VERSION "created by canmatrix"

NS_ :

BS_:

BU_: BMS Third_Party_Device INV VCU U2C

BO_ 3221225472 VECTOR__INDEPENDENT_SIG_MSG: 0 Vector__XXX
 SG_ New_Signal_159 : 0|8@1+ (1,0) [0|0] "" Vector__XXX

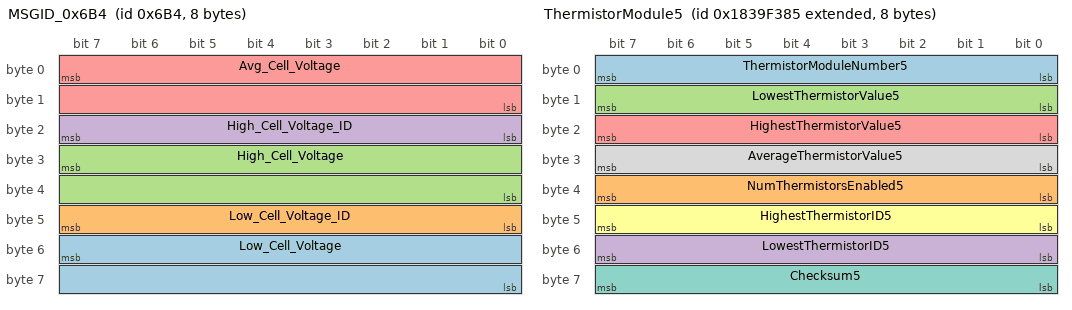
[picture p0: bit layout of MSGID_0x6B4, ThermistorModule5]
BO_ 1716 MSGID_0x6B4: 8 Vector__XXX
 SG_ Low_Cell_Voltage : 55|16@0+ (0.0001,0) [0|0] "V" Vector__XXX
 SG_ Low_Cell_Voltage_ID : 47|8@0+ (1,1720) [0|0] "ID" Vector__XXX
 SG_ High_Cell_Voltage : 31|16@0+ (0.0001,0) [0|0] "V" Vector__XXX
 SG_ High_Cell_Voltage_ID : 23|8@0+ (1,0) [0|0] "ID" Vector__XXX
 SG_ Avg_Cell_Voltage : 7|16@0+ (0.0001,0) [0|0] "V" Vector__XXX

BO_ 2553934725 ThermistorModule5: 8 Vector__XXX
 SG_ ThermistorModuleNumber5 : 0|8@1- (1,0) [0|0] "" Vector__XXX
 SG_ NumThermistorsEnabled5 : 32|8@1- (1,0) [0|0] "" Vector__XXX
 SG_ LowestThermistorValue5 : 8|8@1- (1,0) [0|0] "Celsius" Vector__XXX
 SG_ LowestThermistorID5 : 48|8@1- (1,0) [0|0] "" Vector__XXX
 SG_ HighestThermistorValue5 : 16|8@1- (1,0) [0|0] "Celsius" Vector__XXX
 SG_ HighestThermistorID5 : 40|8@1- (1,0) [0|0] "" Vector__XXX
 SG_ Checksum5 : 56|8@1+ (1,0) [0|0] "" Vector__XXX
 SG_ AverageThermistorValue5 : 24|8@1- (1,0) [0|0] "Celsius" Vector__XXX

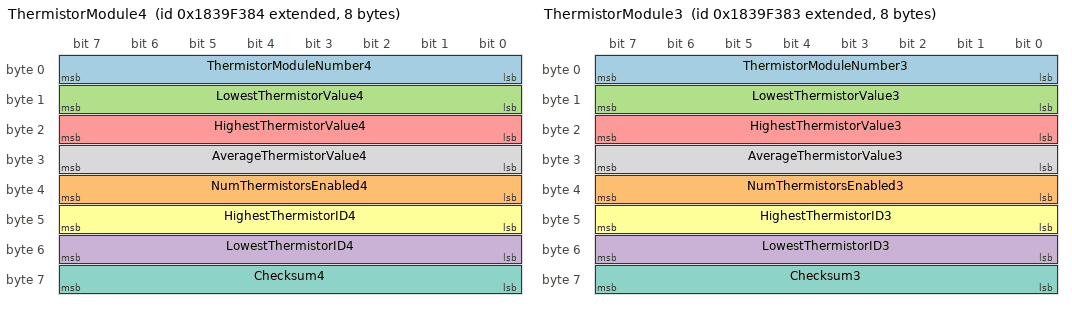
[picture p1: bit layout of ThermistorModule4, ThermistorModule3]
BO_ 2553934724 ThermistorModule4: 8 Vector__XXX
 SG_ ThermistorModuleNumber4 : 0|8@1- (1,0) [0|0] "" Vector__XXX
 SG_ NumThermistorsEnabled4 : 32|8@1- (1,0) [0|0] "" Vector__XXX
 SG_ LowestThermistorValue4 : 8|8@1- (1,0) [0|0] "Celsius" Vector__XXX
 SG_ LowestThermistorID4 : 48|8@1- (1,0) [0|0] "" Vector__XXX
 SG_ HighestThermistorValue4 : 16|8@1- (1,0) [0|0] "Celsius" Vector__XXX
 SG_ HighestThermistorID4 : 40|8@1- (1,0) [0|0] "" Vector__XXX
 SG_ Checksum4 : 56|8@1+ (1,0) [0|0] "" Vector__XXX
 SG_ AverageThermistorValue4 : 24|8@1- (1,0) [0|0] "Celsius" Vector__XXX

BO_ 2553934723 ThermistorModule3: 8 Vector__XXX
 SG_ ThermistorModuleNumber3 : 0|8@1- (1,0) [0|0] "" Vector__XXX
 SG_ NumThermistorsEnabled3 : 32|8@1- (1,0) [0|0] "" Vector__XXX
 SG_ LowestThermistorValue3 : 8|8@1- (1,0) [0|0] "Celsius" Vector__XXX
 SG_ LowestThermistorID3 : 48|8@1- (1,0) [0|0] "" Vector__XXX
 SG_ HighestThermistorValue3 : 16|8@1- (1,0) [0|0] "Celsius" Vector__XXX
 SG_ HighestThermistorID3 : 40|8@1- (1,0) [0|0] "" Vector__XXX
 SG_ Checksum3 : 56|8@1+ (1,0) [0|0] "" Vector__XXX
 SG_ AverageThermistorValue3 : 24|8@1- (1,0) [0|0] "Celsius" Vector__XXX

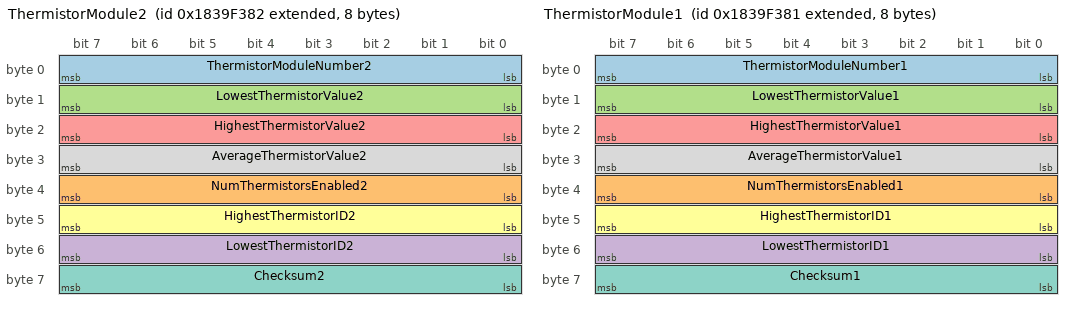
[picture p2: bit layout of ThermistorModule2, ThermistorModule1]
BO_ 2553934722 ThermistorModule2: 8 Vector__XXX
 SG_ ThermistorModuleNumber2 : 0|8@1- (1,0) [0|0] "" Vector__XXX
 SG_ NumThermistorsEnabled2 : 32|8@1- (1,0) [0|0] "" Vector__XXX
 SG_ LowestThermistorValue2 : 8|8@1- (1,0) [0|0] "Celsius" Vector__XXX
 SG_ LowestThermistorID2 : 48|8@1- (1,0) [0|0] "" Vector__XXX
 SG_ HighestThermistorValue2 : 16|8@1- (1,0) [0|0] "Celsius" Vector__XXX
 SG_ HighestThermistorID2 : 40|8@1- (1,0) [0|0] "" Vector__XXX
 SG_ Checksum2 : 56|8@1+ (1,0) [0|0] "" Vector__XXX
 SG_ AverageThermistorValue2 : 24|8@1- (1,0) [0|0] "Celsius" Vector__XXX

BO_ 2553934721 ThermistorModule1: 8 Vector__XXX
 SG_ ThermistorModuleNumber1 : 0|8@1- (1,0) [0|0] "" Vector__XXX
 SG_ NumThermistorsEnabled1 : 32|8@1- (1,0) [0|0] "" Vector__XXX
 SG_ LowestThermistorValue1 : 8|8@1- (1,0) [0|0] "Celsius" Vector__XXX
 SG_ LowestThermistorID1 : 48|8@1- (1,0) [0|0] "" Vector__XXX
 SG_ HighestThermistorValue1 : 16|8@1- (1,0) [0|0] "Celsius" Vector__XXX
 SG_ HighestThermistorID1 : 40|8@1- (1,0) [0|0] "" Vector__XXX
 SG_ Checksum1 : 56|8@1+ (1,0) [0|0] "" Vector__XXX
 SG_ AverageThermistorValue1 : 24|8@1- (1,0) [0|0] "Celsius" Vector__XXX

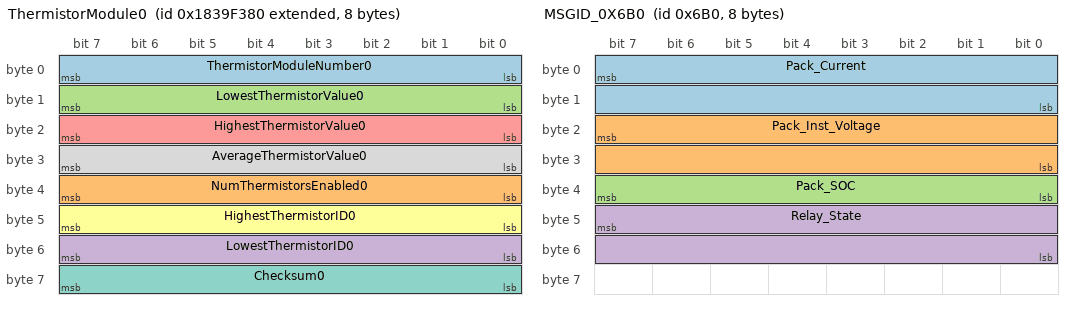
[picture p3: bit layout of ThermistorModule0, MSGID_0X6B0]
BO_ 2553934720 ThermistorModule0: 8 Vector__XXX
 SG_ ThermistorModuleNumber0 : 0|8@1- (1,0) [0|0] "" Vector__XXX
 SG_ NumThermistorsEnabled0 : 32|8@1- (1,0) [0|0] "" Vector__XXX
 SG_ LowestThermistorValue0 : 8|8@1- (1,0) [0|0] "Celsius" Vector__XXX
 SG_ LowestThermistorID0 : 48|8@1- (1,0) [0|0] "" Vector__XXX
 SG_ HighestThermistorValue0 : 16|8@1- (1,0) [0|0] "Celsius" Vector__XXX
 SG_ HighestThermistorID0 : 40|8@1- (1,0) [0|0] "" Vector__XXX
 SG_ Checksum0 : 56|8@1+ (1,0) [0|0] "" Vector__XXX
 SG_ AverageThermistorValue0 : 24|8@1- (1,0) [0|0] "Celsius" Vector__XXX

BO_ 1712 MSGID_0X6B0: 8 BMS
 SG_ Pack_Current : 7|16@0+ (0.1,0) [0|0] "A"  Third_Party_Device
 SG_ Pack_Inst_Voltage : 23|16@0+ (0.1,0) [0|0] "V"  Third_Party_Device
 SG_ Pack_SOC : 39|8@0+ (0.5,0) [0|0] "Percent"  Third_Party_Device
 SG_ Relay_State : 47|16@0+ (1,0) [0|0] ""  Third_Party_Device

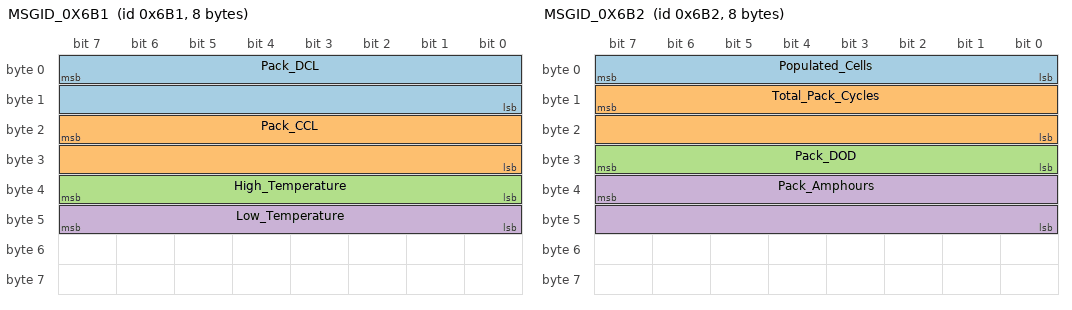
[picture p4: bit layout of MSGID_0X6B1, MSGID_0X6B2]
BO_ 1713 MSGID_0X6B1: 8 BMS
 SG_ Pack_DCL : 7|16@0+ (1,0) [0|0] "A"  Third_Party_Device
 SG_ Pack_CCL : 23|16@0+ (1,0) [0|0] "Amp"  Third_Party_Device
 SG_ High_Temperature : 39|8@0+ (1,0) [0|0] "Celsius"  Third_Party_Device
 SG_ Low_Temperature : 47|8@0+ (1,0) [0|0] "Celsius"  Third_Party_Device

BO_ 1714 MSGID_0X6B2: 8 BMS
 SG_ Populated_Cells : 7|8@0+ (1,0) [0|0] ""  Third_Party_Device
 SG_ Total_Pack_Cycles : 15|16@0+ (1,0) [0|0] ""  Third_Party_Device
 SG_ Pack_DOD : 31|8@0+ (0.5,0) [0|0] "Percent"  Third_Party_Device
 SG_ Pack_Amphours : 39|16@0+ (0.1,0) [0|0] "Amphours"  Third_Party_Device

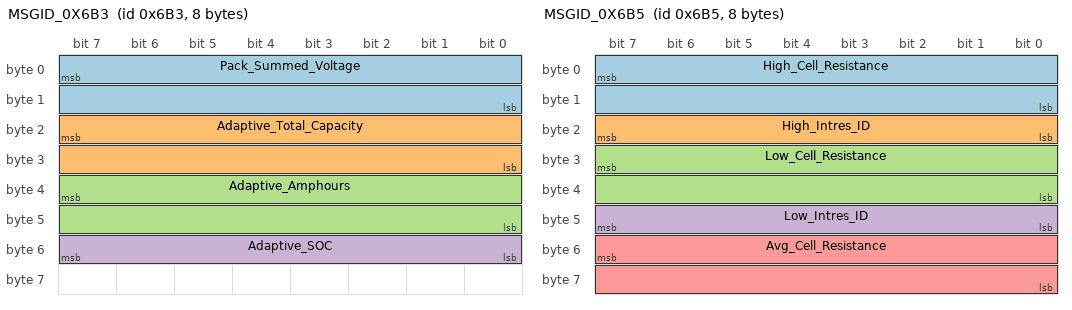
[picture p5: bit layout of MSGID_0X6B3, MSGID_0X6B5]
BO_ 1715 MSGID_0X6B3: 8 BMS
 SG_ Pack_Summed_Voltage : 7|16@0+ (0.01,0) [0|0] "V"  Third_Party_Device
 SG_ Adaptive_Total_Capacity : 23|16@0+ (0.1,0) [0|0] "Amphours"  Third_Party_Device
 SG_ Adaptive_Amphours : 39|16@0+ (0.1,0) [0|0] "Amphours"  Third_Party_Device
 SG_ Adaptive_SOC : 55|8@0+ (0.5,0) [0|0] "Percent"  Third_Party_Device

BO_ 1717 MSGID_0X6B5: 8 BMS
 SG_ High_Cell_Resistance : 7|16@0+ (0.01,0) [0|0] "mOhm"  Third_Party_Device
 SG_ High_Intres_ID : 23|8@0+ (1,0) [0|0] "ID"  Third_Party_Device
 SG_ Low_Cell_Resistance : 31|16@0+ (0.01,0) [0|0] "mOhm"  Third_Party_Device
 SG_ Low_Intres_ID : 47|8@0+ (1,0) [0|0] "ID"  Third_Party_Device
 SG_ Avg_Cell_Resistance : 55|16@0+ (0.01,0) [0|0] "mOhm"  Third_Party_Device

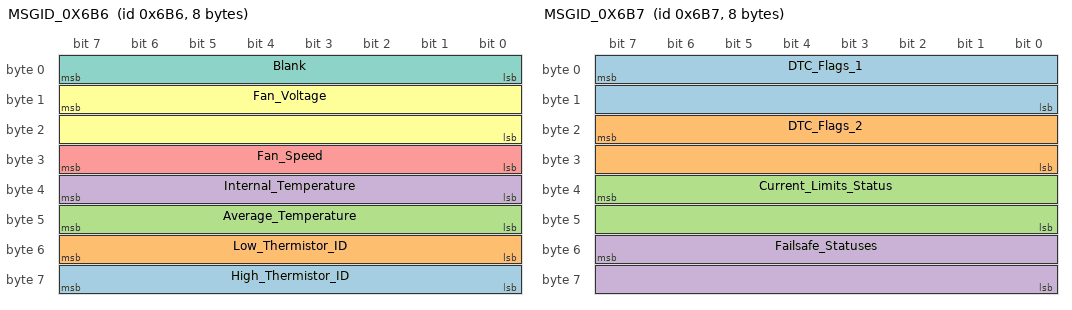
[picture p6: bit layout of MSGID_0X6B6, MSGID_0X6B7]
BO_ 1718 MSGID_0X6B6: 8 BMS
 SG_ High_Thermistor_ID : 63|8@0+ (1,0) [0|0] "ID"  Third_Party_Device
 SG_ Low_Thermistor_ID : 55|8@0+ (1,0) [0|0] "ID"  Third_Party_Device
 SG_ Average_Temperature : 47|8@0+ (1,0) [0|0] "Celsius"  Third_Party_Device
 SG_ Internal_Temperature : 39|8@0+ (1,0) [0|0] "Celsius"  Third_Party_Device
 SG_ Fan_Speed : 31|8@0+ (1,0) [0|0] "Speed"  Third_Party_Device
 SG_ Fan_Voltage : 15|16@0+ (0.01,0) [0|0] "Volts"  Third_Party_Device
 SG_ Blank : 7|8@0+ (1,0) [0|0] ""  Third_Party_Device

BO_ 1719 MSGID_0X6B7: 8 BMS
 SG_ DTC_Flags_1 : 7|16@0+ (1,0) [0|0] ""  Third_Party_Device
 SG_ DTC_Flags_2 : 23|16@0+ (1,0) [0|0] ""  Third_Party_Device
 SG_ Current_Limits_Status : 39|16@0+ (1,0) [0|0] ""  Third_Party_Device
 SG_ Failsafe_Statuses : 55|16@0+ (1,0) [0|0] ""  Third_Party_Device

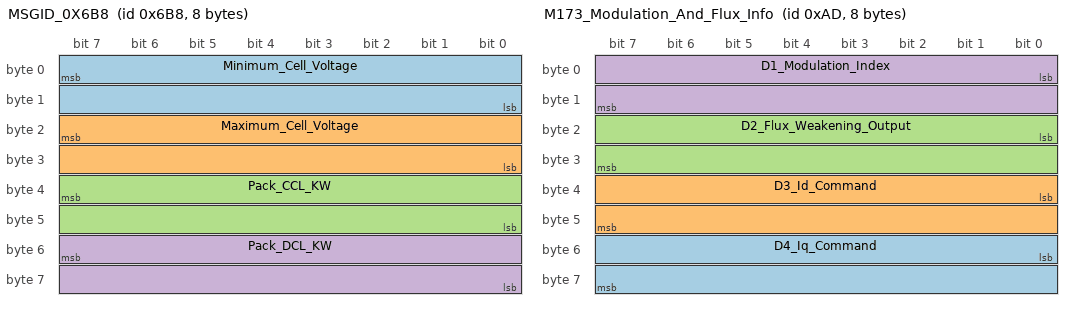
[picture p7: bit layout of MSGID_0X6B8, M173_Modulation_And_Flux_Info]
BO_ 1720 MSGID_0X6B8: 8 BMS
 SG_ Minimum_Cell_Voltage : 7|16@0+ (0.0001,0) [0|0] "Volts"  Third_Party_Device
 SG_ Maximum_Cell_Voltage : 23|16@0+ (0.0001,0) [0|0] "Volts"  Third_Party_Device
 SG_ Pack_CCL_KW : 39|16@0+ (0.1,0) [0|0] "kW"  Third_Party_Device
 SG_ Pack_DCL_KW : 55|16@0+ (0.1,0) [0|0] "kW"  Third_Party_Device

BO_ 173 M173_Modulation_And_Flux_Info: 8 INV
 SG_ D4_Iq_Command : 48|16@1- (0.1,0) [-3276.8|3276.7] "A" Vector__XXX
 SG_ D3_Id_Command : 32|16@1- (0.1,0) [-3276.8|3276.7] "A" Vector__XXX
 SG_ D2_Flux_Weakening_Output : 16|16@1- (0.1,0) [-3276.8|3276.7] "A" Vector__XXX
 SG_ D1_Modulation_Index : 0|16@1- (0.01,0) [-327.68|327.67] "" Vector__XXX

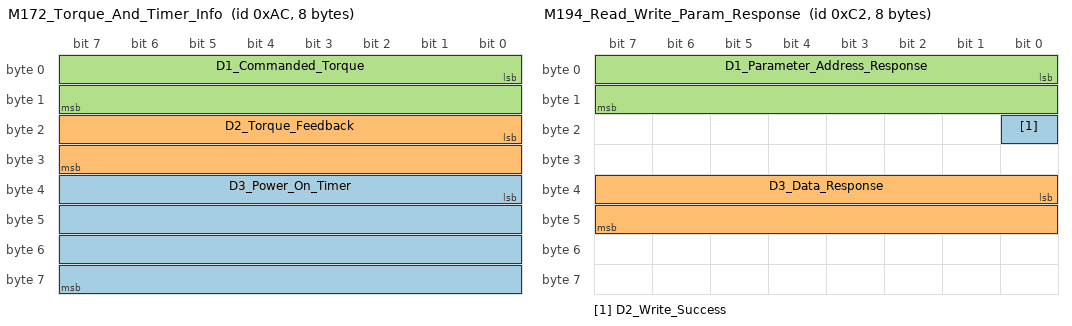
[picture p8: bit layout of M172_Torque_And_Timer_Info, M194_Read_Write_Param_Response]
BO_ 172 M172_Torque_And_Timer_Info: 8 INV
 SG_ D3_Power_On_Timer : 32|32@1+ (1,0) [0|4294967295] "Sec" Vector__XXX
 SG_ D2_Torque_Feedback : 16|16@1- (0.1,0) [-3276.8|3276.7] "Nm" Vector__XXX
 SG_ D1_Commanded_Torque : 0|16@1- (0.1,0) [-3276.8|3276.7] "Nm" Vector__XXX

BO_ 194 M194_Read_Write_Param_Response: 8 INV
 SG_ D2_Write_Success : 16|1@1+ (1,0) [0|1] "" Vector__XXX
 SG_ D3_Data_Response : 32|16@1- (1,0) [-32768|32767] "" Vector__XXX
 SG_ D1_Parameter_Address_Response : 0|16@1+ (1,0) [0|65535] "" Vector__XXX

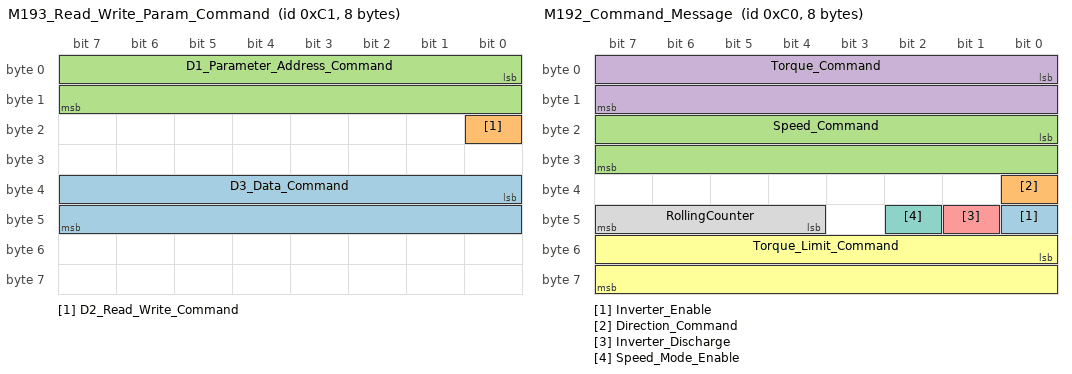
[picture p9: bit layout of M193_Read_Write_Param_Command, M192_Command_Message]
BO_ 193 M193_Read_Write_Param_Command: 8 VCU
 SG_ D3_Data_Command : 32|16@1- (1,0) [-32768|32767] "" Vector__XXX
 SG_ D2_Read_Write_Command : 16|1@1+ (1,0) [0|1] "" Vector__XXX
 SG_ D1_Parameter_Address_Command : 0|16@1+ (1,0) [0|65535] "" Vector__XXX

BO_ 192 M192_Command_Message: 8 VCU
 SG_ Inverter_Enable : 40|1@1+ (1,0) [0|1] "Bit" Vector__XXX
 SG_ Direction_Command : 32|1@1+ (1,0) [0|1] "Bit" Vector__XXX
 SG_ Speed_Command : 16|16@1- (1,0) [-32768|32767] "rpm" Vector__XXX
 SG_ Torque_Command : 0|16@1- (0.1,0) [-3276.8|3276.7] "Nm" Vector__XXX
 SG_ Inverter_Discharge : 41|1@1+ (1,0) [0|1] "Bit" Vector__XXX
 SG_ Torque_Limit_Command : 48|16@1- (0.1,0) [-3276.8|3276.7] "Nm" Vector__XXX
 SG_ Speed_Mode_Enable : 42|1@1+ (1,0) [0|1] "Bit" Vector__XXX
 SG_ RollingCounter : 44|4@1+ (1,0) [0|15] "Bits" Vector__XXX

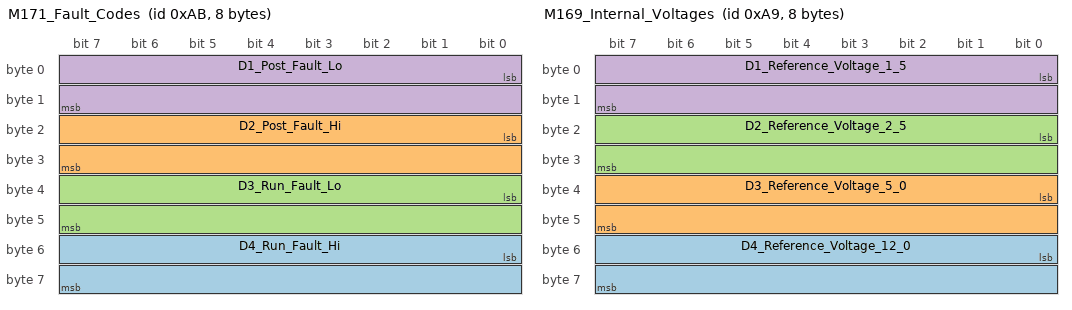
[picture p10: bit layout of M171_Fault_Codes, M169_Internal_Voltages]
BO_ 171 M171_Fault_Codes: 8 INV
 SG_ D4_Run_Fault_Hi : 48|16@1+ (1,0) [0|65535] "" Vector__XXX
 SG_ D2_Post_Fault_Hi : 16|16@1+ (1,0) [0|65535] "" Vector__XXX
 SG_ D3_Run_Fault_Lo : 32|16@1+ (1,0) [0|65535] "" Vector__XXX
 SG_ D1_Post_Fault_Lo : 0|16@1+ (1,0) [0|65535] "" Vector__XXX

BO_ 170 M170_Internal_States: 8 INV
 SG_ D7_Direction_Command : 56|1@1+ (1,0) [0|1] "" Vector__XXX
 SG_ D6_Inverter_Enable_State : 48|1@1+ (1,0) [0|1] "" Vector__XXX
 SG_ D3_Relay_3_Status : 26|1@1+ (1,0) [0|1] "" Vector__XXX
 SG_ D3_Relay_4_Status : 27|1@1+ (1,0) [0|1] "" Vector__XXX
 SG_ D3_Relay_2_Status : 25|1@1+ (1,0) [0|1] "" Vector__XXX
 SG_ D4_Inverter_Run_Mode : 32|1@1+ (1,0) [0|1] "" Vector__XXX
 SG_ D5_Inverter_Command_Mode : 40|1@1+ (1,0) [0|1] "" Vector__XXX
 SG_ D3_Relay_1_Status : 24|1@1+ (1,0) [0|1] "" Vector__XXX
 SG_ D2_Inverter_State : 16|8@1+ (1,0) [0|255] "" Vector__XXX
 SG_ D1_VSM_State : 0|8@1+ (1,0) [0|15] "" Vector__XXX
 SG_ D6_Inverter_Enable_Lockout : 55|1@1+ (1,0) [0|1] "" Vector__XXX
 SG_ D4_Inverter_Discharge_State : 37|3@1+ (1,0) [0|7] "" Vector__XXX
 SG_ D3_Relay_5_Status : 28|1@1+ (1,0) [0|1] "" Vector__XXX
 SG_ D3_Relay_6_Status : 29|1@1+ (1,0) [0|1] "" Vector__XXX
 SG_ D7_BMS_Active : 57|1@1+ (1,0) [0|1] "" Vector__XXX
 SG_ D7_BMS_Torque_Limiting : 58|1@1+ (1,0) [0|1] "" Vector__XXX
 SG_ D7_Max_Speed_Limiting : 59|1@1+ (1,0) [0|1] "" Vector__XXX
 SG_ D7_Low_Speed_Limiting : 61|1@1+ (1,0) [0|1] "" Vector__XXX
 SG_ D5_Rolling_Counter : 44|4@1+ (1,0) [0|15] "" Vector__XXX
 SG_ D1_PWM_Frequency : 8|8@1+ (1,0) [0|255] "kHz" Vector__XXX
 SG_ D6_Start_Mode_Active : 54|1@1+ (1,0) [0|1] "" Vector__XXX

BO_ 169 M169_Internal_Voltages: 8 INV
 SG_ D4_Reference_Voltage_12_0 : 48|16@1- (0.01,0) [-327.68|327.67] "V" Vector__XXX
 SG_ D3_Reference_Voltage_5_0 : 32|16@1- (0.01,0) [-327.68|327.67] "V" Vector__XXX
 SG_ D2_Reference_Voltage_2_5 : 16|16@1- (0.01,0) [-327.68|327.67] "V" Vector__XXX
 SG_ D1_Reference_Voltage_1_5 : 0|16@1- (0.01,0) [-327.68|327.67] "V" Vector__XXX

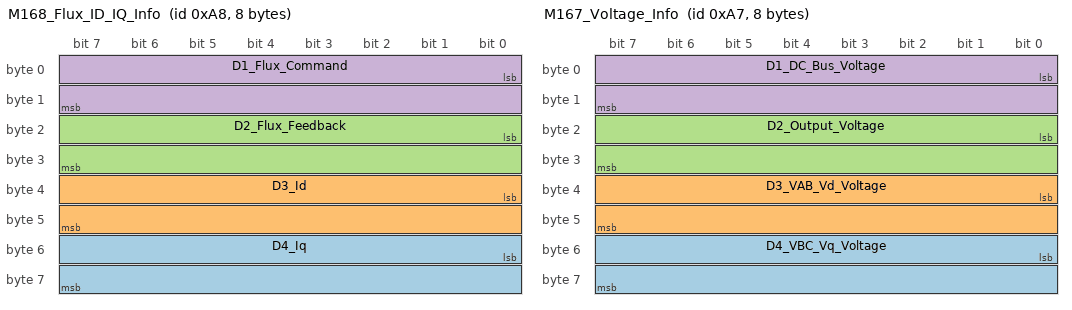
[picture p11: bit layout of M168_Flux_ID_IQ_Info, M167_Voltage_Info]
BO_ 168 M168_Flux_ID_IQ_Info: 8 INV
 SG_ D4_Iq : 48|16@1- (0.1,0) [-3276.8|3276.7] "A" Vector__XXX
 SG_ D3_Id : 32|16@1- (0.1,0) [-3276.8|3276.7] "A" Vector__XXX
 SG_ D2_Flux_Feedback : 16|16@1- (0.001,0) [-32.768|32.767] "Wb" Vector__XXX
 SG_ D1_Flux_Command : 0|16@1- (0.001,0) [-32.768|32.767] "Wb" Vector__XXX

BO_ 167 M167_Voltage_Info: 8 INV
 SG_ D4_VBC_Vq_Voltage : 48|16@1- (0.1,0) [-3276.8|3276.7] "V" Vector__XXX
 SG_ D3_VAB_Vd_Voltage : 32|16@1- (0.1,0) [-3276.8|3276.7] "V" Vector__XXX
 SG_ D2_Output_Voltage : 16|16@1- (0.1,0) [-3276.8|3276.7] "V" Vector__XXX
 SG_ D1_DC_Bus_Voltage : 0|16@1- (0.1,0) [-3276.8|3276.7] "V" Vector__XXX

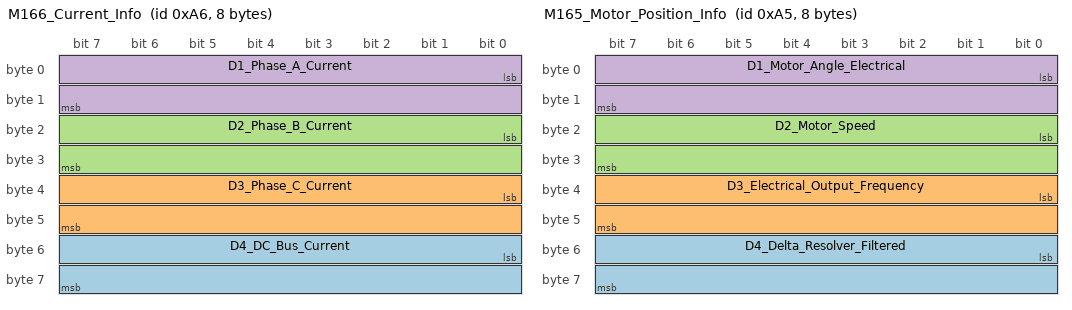
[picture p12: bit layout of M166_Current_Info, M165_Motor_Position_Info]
BO_ 166 M166_Current_Info: 8 INV
 SG_ D4_DC_Bus_Current : 48|16@1- (0.1,0) [-3276.8|3276.7] "A" Vector__XXX
 SG_ D3_Phase_C_Current : 32|16@1- (0.1,0) [-3276.8|3276.7] "A" Vector__XXX
 SG_ D2_Phase_B_Current : 16|16@1- (0.1,0) [-3276.8|3276.7] "A" Vector__XXX
 SG_ D1_Phase_A_Current : 0|16@1- (0.1,0) [-3276.8|3276.7] "A" Vector__XXX

BO_ 165 M165_Motor_Position_Info: 8 INV
 SG_ D4_Delta_Resolver_Filtered : 48|16@1- (0.1,0) [-3276.8|3276.7] "deg" Vector__XXX
 SG_ D3_Electrical_Output_Frequency : 32|16@1- (0.1,0) [-3276.8|3276.7] "hz" Vector__XXX
 SG_ D2_Motor_Speed : 16|16@1- (1,0) [-32768|32767] "rpm" Vector__XXX
 SG_ D1_Motor_Angle_Electrical : 0|16@1- (0.1,0) [-3276.8|3276.7] "deg" Vector__XXX

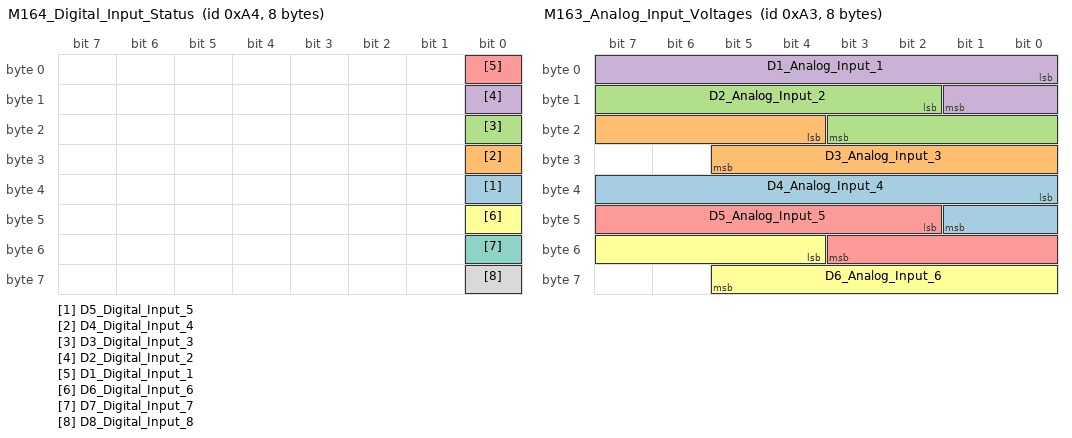
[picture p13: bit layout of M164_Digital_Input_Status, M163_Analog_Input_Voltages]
BO_ 164 M164_Digital_Input_Status: 8 INV
 SG_ D5_Digital_Input_5 : 32|1@1+ (1,0) [0|1] "boolean" Vector__XXX
 SG_ D4_Digital_Input_4 : 24|1@1+ (1,0) [0|1] "boolean" Vector__XXX
 SG_ D3_Digital_Input_3 : 16|1@1+ (1,0) [0|1] "boolean" Vector__XXX
 SG_ D2_Digital_Input_2 : 8|1@1+ (1,0) [0|1] "boolean" Vector__XXX
 SG_ D1_Digital_Input_1 : 0|1@1+ (1,0) [0|1] "boolean" Vector__XXX
 SG_ D6_Digital_Input_6 : 40|1@1+ (1,0) [0|1] "boolean" Vector__XXX
 SG_ D7_Digital_Input_7 : 48|1@1+ (1,0) [0|1] "boolean" Vector__XXX
 SG_ D8_Digital_Input_8 : 56|1@1+ (1,0) [0|1] "boolean" Vector__XXX

BO_ 163 M163_Analog_Input_Voltages: 8 INV
 SG_ D4_Analog_Input_4 : 32|10@1- (0.01,0) [-5.12|5.11] "V" Vector__XXX
 SG_ D3_Analog_Input_3 : 20|10@1- (0.01,0) [-5.12|5.11] "V" Vector__XXX
 SG_ D2_Analog_Input_2 : 10|10@1- (0.01,0) [-5.12|5.11] "V" Vector__XXX
 SG_ D1_Analog_Input_1 : 0|10@1- (0.01,0) [-5.12|5.11] "V" Vector__XXX
 SG_ D5_Analog_Input_5 : 42|10@1- (0.01,0) [-5.12|5.11] "V" Vector__XXX
 SG_ D6_Analog_Input_6 : 52|10@1- (0.01,0) [-5.12|5.11] "V" Vector__XXX

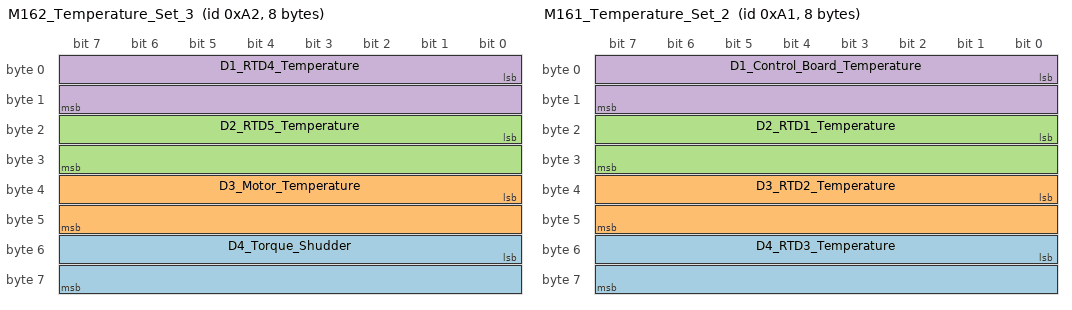
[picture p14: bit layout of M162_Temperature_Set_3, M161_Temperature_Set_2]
BO_ 162 M162_Temperature_Set_3: 8 INV
 SG_ D4_Torque_Shudder : 48|16@1- (0.1,0) [-3276.8|3276.7] "Nm" Vector__XXX
 SG_ D3_Motor_Temperature : 32|16@1- (0.1,0) [-3276.8|3276.7] "degC" Vector__XXX
 SG_ D2_RTD5_Temperature : 16|16@1- (0.1,0) [-3276.8|3276.7] "degC" Vector__XXX
 SG_ D1_RTD4_Temperature : 0|16@1- (0.1,0) [-3276.8|3276.7] "degC" Vector__XXX

BO_ 161 M161_Temperature_Set_2: 8 INV
 SG_ D4_RTD3_Temperature : 48|16@1- (0.1,0) [-3276.8|3276.7] "degC" Vector__XXX
 SG_ D3_RTD2_Temperature : 32|16@1- (0.1,0) [-3276.8|3276.7] "degC" Vector__XXX
 SG_ D2_RTD1_Temperature : 16|16@1- (0.1,0) [-3276.8|3276.7] "degC" Vector__XXX
 SG_ D1_Control_Board_Temperature : 0|16@1- (0.1,0) [-3276.8|3276.7] "degC" Vector__XXX

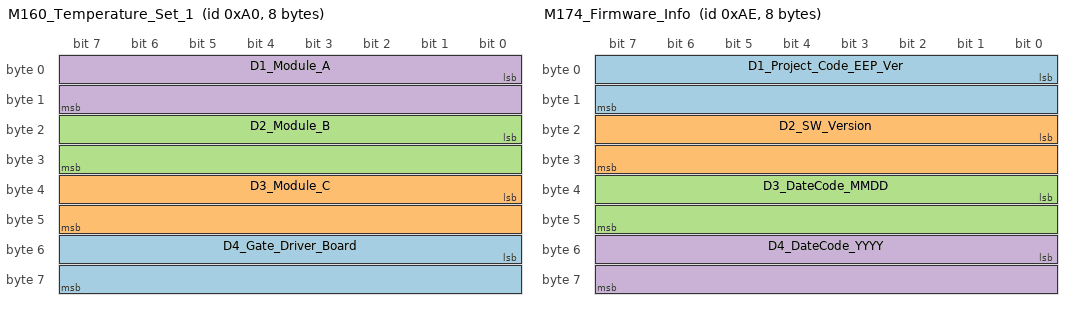
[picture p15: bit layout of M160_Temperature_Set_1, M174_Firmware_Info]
BO_ 160 M160_Temperature_Set_1: 8 INV
 SG_ D4_Gate_Driver_Board : 48|16@1- (0.1,0) [-3276.8|3276.7] "degC" Vector__XXX
 SG_ D3_Module_C : 32|16@1- (0.1,0) [-3276.8|3276.7] "degC" Vector__XXX
 SG_ D2_Module_B : 16|16@1- (0.1,0) [-3276.8|3276.7] "degC" Vector__XXX
 SG_ D1_Module_A : 0|16@1- (0.1,0) [-3276.8|3276.7] "degC" Vector__XXX

BO_ 174 M174_Firmware_Info: 8 INV
 SG_ D1_Project_Code_EEP_Ver : 0|16@1+ (1,0) [0|65535] "" Vector__XXX
 SG_ D2_SW_Version : 16|16@1+ (1,0) [0|65535] "" Vector__XXX
 SG_ D3_DateCode_MMDD : 32|16@1+ (1,0) [0|65535] "" Vector__XXX
 SG_ D4_DateCode_YYYY : 48|16@1+ (1,0) [0|65535] "" Vector__XXX

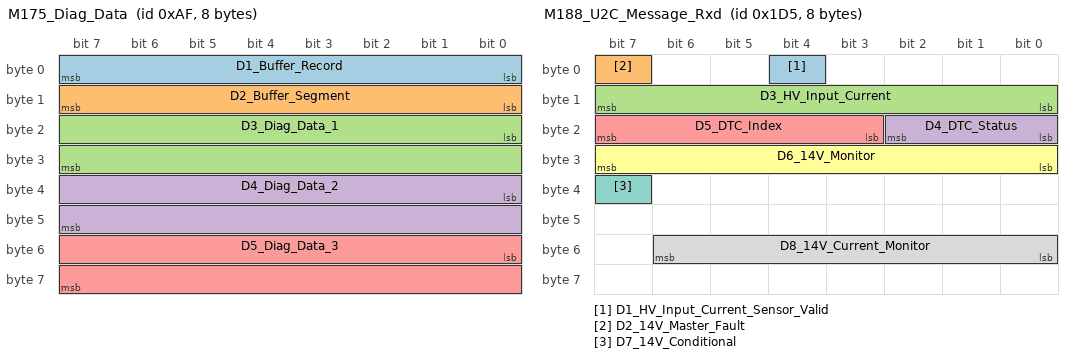
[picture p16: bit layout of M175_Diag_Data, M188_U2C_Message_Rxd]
BO_ 175 M175_Diag_Data: 8 INV
 SG_ D1_Buffer_Record : 0|8@1+ (1,0) [0|255] "" Vector__XXX
 SG_ D2_Buffer_Segment : 8|8@1+ (1,0) [0|5] "" Vector__XXX
 SG_ D3_Diag_Data_1 : 16|16@1- (1,0) [-32768|32767] "" Vector__XXX
 SG_ D4_Diag_Data_2 : 32|16@1- (1,0) [-32768|32767] "" Vector__XXX
 SG_ D5_Diag_Data_3 : 48|16@1- (1,0) [-32768|32767] "" Vector__XXX

BO_ 471 M187_U2C_Command_Txd: 8 INV
 SG_ D1_ID_Byte : 0|8@1+ (1,0) [0|255] "" Vector__XXX
 SG_ D2_Setpoint_Calc : 8|8@1+ (1,0) [0|255] "" Vector__XXX

BO_ 469 M188_U2C_Message_Rxd: 8 U2C
 SG_ D1_HV_Input_Current_Sensor_Valid : 4|1@1+ (1,0) [0|1] "" Vector__XXX
 SG_ D2_14V_Master_Fault : 7|1@1+ (1,0) [0|1] "" Vector__XXX
 SG_ D3_HV_Input_Current : 8|8@1+ (1,0) [0|255] "" Vector__XXX
 SG_ D4_DTC_Status : 16|3@1+ (1,0) [0|7] "" Vector__XXX
 SG_ D5_DTC_Index : 19|5@1+ (1,0) [0|31] "" Vector__XXX
 SG_ D6_14V_Monitor : 24|8@1+ (1,0) [0|255] "" Vector__XXX
 SG_ D7_14V_Conditional : 39|1@1+ (1,0) [0|1] "" Vector__XXX
 SG_ D8_14V_Current_Monitor : 48|7@1+ (1,0) [0|127] "" Vector__XXX

BO_ 514 MSGID_0x202: 8 U2C
 SG_ Maxmimum_Pack_DCL : 0|16@1+ (1,0) [0|1000] "A" Vector__XXX
 SG_ Maxmimum_Pack_CCL : 16|16@1+ (1,0) [0|1000] "A" Vector__XXX

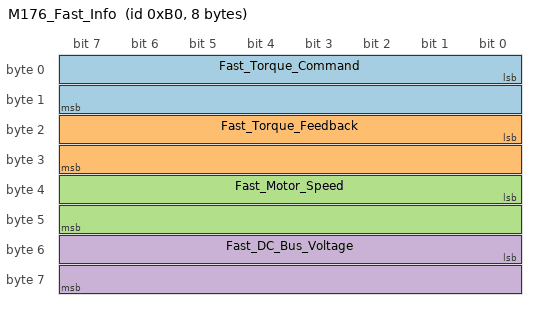
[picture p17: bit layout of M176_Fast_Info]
BO_ 176 M176_Fast_Info: 8 INV
 SG_ Fast_Torque_Command : 0|16@1- (0.1,0) [-3276.8|3276.7] "Nm" Vector__XXX
 SG_ Fast_Torque_Feedback : 16|16@1- (0.1,0) [-3276.8|3276.7] "Nm" Vector__XXX
 SG_ Fast_Motor_Speed : 32|16@1- (1,0) [-32768|32767] "rpm" Vector__XXX
 SG_ Fast_DC_Bus_Voltage : 48|16@1- (0.1,0) [-3276.8|3276.7] "V" Vector__XXX

CM_ BU_ INV "The Cascadia Motion inverter";
CM_ BU_ VCU "The system vehicle control unit";
CM_ BU_ U2C "Delphi DC/DC Converter";
CM_ BO_ 3221225472 "This is a message for not used signals, created by Vector CANdb++ DBC OLE DB Provider.";
CM_ BO_ 1712 "This ID Transmits at 8 ms.";
CM_ BO_ 1713 "This ID Transmits at 8 ms.";
CM_ BO_ 1714 "This ID Transmits at 8 ms.";
CM_ BO_ 1715 "This ID Transmits at 8 ms.";
CM_ BO_ 1717 "This ID Transmits at 8 ms.";
CM_ BO_ 1718 "This ID Transmits at 8 ms.";
CM_ BO_ 1719 "This ID Transmits at 8 ms.";
CM_ BO_ 1720 "This ID Transmits at 8 ms.";
CM_ SG_ 173 D4_Iq_Command "The commanded Q-axis current";
CM_ SG_ 173 D3_Id_Command "The commanded D-axis current";
CM_ SG_ 173 D2_Flux_Weakening_Output "This is the current output of the flux regulator.";
CM_ SG_ 173 D1_Modulation_Index "This is the modulation index. The scale factor is x100. To get the actual modulation index divide the value by 100.";
CM_ SG_ 172 D3_Power_On_Timer "Updated every 3 msec. This will roll over in approximately 150 days!";
CM_ SG_ 172 D2_Torque_Feedback "Estimated motor torque feedback";
CM_ SG_ 172 D1_Commanded_Torque "The commanded Torque";
CM_ BO_ 194 "The inverter response to each Parameter message that is received.";
CM_ SG_ 194 D2_Write_Success "0=Write failure, 1=Success";
CM_ SG_ 194 D3_Data_Response "All EEPROM data is 16 bits and is contained in bytes 4 and 5. Bytes 6 and 7 should be ignored.";
CM_ SG_ 194 D1_Parameter_Address_Response "Valid EEPROM Parameter CAN addresses are between 100 and 499.";
CM_ BO_ 193 "Parameter Message sent as needed by VCU to request info, change EEPROM, or command a function.";
CM_ SG_ 193 D3_Data_Command "All EEPROM data is 16 bits and is contained in bytes 4 and 5.";
CM_ SG_ 193 D2_Read_Write_Command "0=Read, 1=Write";
CM_ SG_ 193 D1_Parameter_Address_Command "Valid EEPROM Parameter CAN addresses are between 100 and 499.";
CM_ BO_ 192 "The command message is used to transmit data to the controller. This message is sent from a user supplied external controller to the PMxxx controller.";
CM_ SG_ 192 Inverter_Enable "0=Inverter OFF, 1 = Inverter ON";
CM_ SG_ 192 Direction_Command "0=CW, 1=CCW as veiwed from the shaft end of the motor";
CM_ SG_ 192 Speed_Command "Speed commandused when in speed mode";
CM_ SG_ 192 Torque_Command "Torque command when in torque mode";
CM_ SG_ 192 Inverter_Discharge "0=Discharge Disable,
=Discharge Enable";
CM_ SG_ 192 Torque_Limit_Command "Torque Limit, set to 0 to keep default";
CM_ SG_ 192 Speed_Mode_Enable "0 = No change to mode, 1 = change to speed mode from torque mode";
CM_ SG_ 192 RollingCounter "Rolling Counter command";
CM_ SG_ 171 D4_Run_Fault_Hi "Each bit represents a fault. Please refer to PM100 Users Manual for details.";
CM_ SG_ 171 D2_Post_Fault_Hi "Each bit represents a fault. Please refer to PM100 Users Manual for details.";
CM_ SG_ 171 D3_Run_Fault_Lo "Each bit represents a fault. Please refer to PM100 Users Manual for details.";
CM_ SG_ 171 D1_Post_Fault_Lo "Each bit represents a fault. Please refer to PM100 Users Manual for details.";
CM_ SG_ 170 D7_Direction_Command "1 = Forward
0 = 'Reverse' if inverter enabled  & 'Stopped' if inverter is disabled";
CM_ SG_ 170 D6_Inverter_Enable_State "0=Inverter Disabled,
1=Inverter Enabled";
CM_ SG_ 170 D3_Relay_3_Status "0=OFF, 1=ON";
CM_ SG_ 170 D3_Relay_4_Status "0=OFF, 1=ON";
CM_ SG_ 170 D3_Relay_2_Status "0=OFF, 1=ON";
CM_ SG_ 170 D4_Inverter_Run_Mode "0=Torque Mode, 1=Speed Mode";
CM_ SG_ 170 D5_Inverter_Command_Mode "0=CAN mode, 1=VSM mode";
CM_ SG_ 170 D3_Relay_1_Status "0=OFF, 1=ON";
CM_ SG_ 170 D2_Inverter_State "Different states for the inverter state machine";
CM_ SG_ 170 D1_VSM_State "Different states for the vehicle state machine";
CM_ SG_ 170 D6_Inverter_Enable_Lockout "0=Lockout Disabled, 1=Lockout Enabled";
CM_ SG_ 170 D4_Inverter_Discharge_State "0 = Disabled, 1 = Enabled, 2 = Speed Check, 3 = Active, 4 = Complete";
CM_ SG_ 170 D3_Relay_5_Status "0=OFF, 1=ON";
CM_ SG_ 170 D3_Relay_6_Status "0=OFF, 1=ON";
CM_ SG_ 170 D7_BMS_Active "0 = BMS Not Active, 1 = BMS Active";
CM_ SG_ 170 D7_BMS_Torque_Limiting "0 = Not Limiting, 1 = Limiting";
CM_ SG_ 170 D7_Max_Speed_Limiting "0 = Not Limiting, 1 = torque limiting due to maximum speed";
CM_ SG_ 170 D7_Low_Speed_Limiting "0 = Not Limiting, 1 = Current limiting due to low motor speed";
CM_ SG_ 170 D5_Rolling_Counter "The current rolling counter value.";
CM_ SG_ 170 D1_PWM_Frequency "The inverter PWM frequency";
CM_ SG_ 170 D6_Start_Mode_Active "If in Key Switch Mode 1 then indicates status of Start input being applied.  0 = not active, 1 = active";
CM_ SG_ 169 D4_Reference_Voltage_12_0 "12V Input Voltage";
CM_ SG_ 169 D3_Reference_Voltage_5_0 "Transducer voltage";
CM_ SG_ 169 D2_Reference_Voltage_2_5 "Internal reference voltage";
CM_ SG_ 169 D1_Reference_Voltage_1_5 "Internal reference voltage";
CM_ SG_ 168 D4_Iq "The measured Iq current";
CM_ SG_ 168 D3_Id "The measured Id current";
CM_ SG_ 168 D2_Flux_Feedback "The estimated flux";
CM_ SG_ 168 D1_Flux_Command "The commanded flux";
CM_ SG_ 167 D4_VBC_Vq_Voltage "Measured value of the voltage between Phase B and Phase C";
CM_ SG_ 167 D3_VAB_Vd_Voltage "Measured value of the voltage betwen phase A and Phase B";
CM_ SG_ 167 D2_Output_Voltage "The calculated value of the output voltage, in peak line-neutral volts";
CM_ SG_ 167 D1_DC_Bus_Voltage "The actual measured value of the DC bus voltage";
CM_ SG_ 166 D4_DC_Bus_Current "The Calculated DC Bus Current";
CM_ SG_ 166 D3_Phase_C_Current "The measured value of Phase C current";
CM_ SG_ 166 D2_Phase_B_Current "The measured value of Phase B current";
CM_ SG_ 166 D1_Phase_A_Current "The measured value of Phase A current";
CM_ SG_ 165 D4_Delta_Resolver_Filtered "Used in calibration of resolver angle adjustment.";
CM_ SG_ 165 D3_Electrical_Output_Frequency "The actual electrical frequency of the inverter";
CM_ SG_ 165 D2_Motor_Speed "The measured speed of the motor";
CM_ SG_ 165 D1_Motor_Angle_Electrical "The Electrical Angle of the motor as read by the encoder or resolver";
CM_ SG_ 164 D5_Digital_Input_5 "Status of Digital Input #5";
CM_ SG_ 164 D4_Digital_Input_4 "Status of Digital Input #4";
CM_ SG_ 164 D3_Digital_Input_3 "Status of Digital Input #3";
CM_ SG_ 164 D2_Digital_Input_2 "Status of Digital Input #2";
CM_ SG_ 164 D1_Digital_Input_1 "Status of Digital Input #1";
CM_ SG_ 164 D6_Digital_Input_6 "Status of Digital Input #6";
CM_ SG_ 164 D7_Digital_Input_7 "Status of Digital Input #7";
CM_ SG_ 164 D8_Digital_Input_8 "Status of Digital Input #8";
CM_ SG_ 163 D4_Analog_Input_4 "Voltage on Analog Input #4";
CM_ SG_ 163 D3_Analog_Input_3 "Voltage on Analog Input #3";
CM_ SG_ 163 D2_Analog_Input_2 "Voltage on Analog Input #2";
CM_ SG_ 163 D1_Analog_Input_1 "Voltage on Analog Input #1";
CM_ SG_ 163 D5_Analog_Input_5 "Voltage on Analog Input #5";
CM_ SG_ 163 D6_Analog_Input_6 "Voltage on Analog Input #6";
CM_ SG_ 162 D4_Torque_Shudder "Shudder compensation value of torque";
CM_ SG_ 162 D3_Motor_Temperature "Motor Temperature Sensor";
CM_ SG_ 162 D2_RTD5_Temperature "RTD 5 (PT1000) Temperature (Gen 2 only)";
CM_ SG_ 162 D1_RTD4_Temperature "RTD 4 (PT1000) Temperature (Gen 2 only)";
CM_ SG_ 161 D4_RTD3_Temperature "RTD input 3 (PT1000) Temperature (Gen 2 only)";
CM_ SG_ 161 D3_RTD2_Temperature "RTD input 2 (PT1000) Temperature";
CM_ SG_ 161 D2_RTD1_Temperature "RTD input 1 (PT1000) Temperature";
CM_ SG_ 161 D1_Control_Board_Temperature "Control Board Temperature";
CM_ SG_ 160 D4_Gate_Driver_Board "Gate Driver Board Temperature";
CM_ SG_ 160 D3_Module_C "IGBT Module C Temperature";
CM_ SG_ 160 D2_Module_B "IGBT Module B Temperature";
CM_ SG_ 160 D1_Module_A "IGBT Module A Temperature";
CM_ BO_ 471 "Enable message sent to Delphi DC/DC converter.";
CM_ BO_ 469 "Response from Delphi DC/DC converter.";
CM_ BO_ 514 "Message sent by BMS for inverter DC current limiting.";
CM_ SG_ 514 Maximum_Pack_DCL "Maximum discharge current from BMS";
CM_ SG_ 514 Maximum_Pack_CCL "Maximum charge current from BMS";
CM_ BO_ 176 "To enable fast message set CAN ACTIVE MSGS HI WORD to 0xFFFE.  Setting to default value of 0xFFFF will disable the fast message.";
CM_ SG_ 176 Fast_Torque_Command "The commanded torque";
CM_ SG_ 176 Fast_Torque_Feedback "The estimated torque";
CM_ SG_ 176 Fast_Motor_Speed "Motor speed";
CM_ SG_ 176 Fast_DC_Bus_Voltage "DC Bus Voltage";
BA_DEF_ BO_  "GenMsgCycleTime" INT 0 100000;
BA_DEF_ SG_  "SystemSignalLongSymbol" STRING ;
BA_DEF_DEF_  "GenMsgCycleTime" 0;
BA_DEF_DEF_  "SystemSignalLongSymbol" "";
BA_ "GenMsgCycleTime" BO_ 172 10;
BA_ "GenMsgCycleTime" BO_ 192 5;
BA_ "GenMsgCycleTime" BO_ 171 100;
BA_ "GenMsgCycleTime" BO_ 170 100;
BA_ "GenMsgCycleTime" BO_ 169 100;
BA_ "GenMsgCycleTime" BO_ 168 10;
BA_ "GenMsgCycleTime" BO_ 167 10;
BA_ "GenMsgCycleTime" BO_ 166 10;
BA_ "GenMsgCycleTime" BO_ 165 10;
BA_ "GenMsgCycleTime" BO_ 164 10;
BA_ "GenMsgCycleTime" BO_ 163 10;
BA_ "GenMsgCycleTime" BO_ 162 100;
BA_ "GenMsgCycleTime" BO_ 161 100;
BA_ "GenMsgCycleTime" BO_ 160 100;
BA_ "GenMsgCycleTime" BO_ 176 3;
BA_ "SystemSignalLongSymbol" SG_ 469 D1_HV_Input_Current_Sensor_Valid "D1_HV_Input_Current_Sensor_Validity";
VAL_ 192 Inverter_Enable 0 "Turn the inverter OFF" 1 "Turn the Inverter ON" ;
VAL_ 192 Direction_Command 0 "CW" 1 "CCW" ;
VAL_ 192 Inverter_Discharge 0 "Discharge Disable" 1 "Discharge Enable (if EEPROM parameter is set)" ;
VAL_ 170 D2_Inverter_State 0 "Power up" 1 "Stop" 2 "Open Loop" 3 "Closed Loop" 4 "Internal State" 5 "Internal State" 6 "Internal State" 7 "Internal State" 8 "Idle Run" 9 "Idle Stop" 10 "Internal State" 11 "Intern State" 12 "Internal State" ;
VAL_ 170 D1_VSM_State 0 "VSM Start State" 1 "Pre-Charge Init state" 2 "pre-charge active state" 3 "pre-charge complete state" 4 "VSM wait state" 5 "VSM ready state" 6 "Motor Running State" 7 "blink fault code state" 14 "Shutdown state for Key Switch Mode 1" 15 "Reset the inverter" ;
